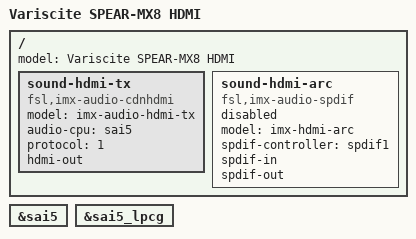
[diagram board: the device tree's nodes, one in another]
/*
 * Copyright 2019 Variscite Ltd.
 *
 * This program is free software; you can redistribute it and/or
 * modify it under the terms of the GNU General Public License
 * as published by the Free Software Foundation; either version 2
 * of the License, or (at your option) any later version.
 *
 * This program is distributed in the hope that it will be useful,
 * but WITHOUT ANY WARRANTY; without even the implied warranty of
 * MERCHANTABILITY or FITNESS FOR A PARTICULAR PURPOSE.  See the
 * GNU General Public License for more details.
 */

#include "imx8qm-var-spear-common.dtsi"
#include "imx8qm-var-spear-hdmi.dtsi"

/ {
	model = "Variscite SPEAR-MX8 HDMI";
};

/ {
    sound-hdmi-tx {
        compatible = "fsl,imx-audio-cdnhdmi";
        model = "imx-audio-hdmi-tx";
        audio-cpu = <&sai5>;
        protocol = <1>;
        hdmi-out;
    };

	sound-hdmi-arc {
		compatible = "fsl,imx-audio-spdif";
		model = "imx-hdmi-arc";
		spdif-controller = <&spdif1>;
		spdif-in;
		spdif-out;
		status = "disabled";
	};
};

&sai5 {
	status = "okay";
};

&sai5_lpcg {
	status = "okay";
};
